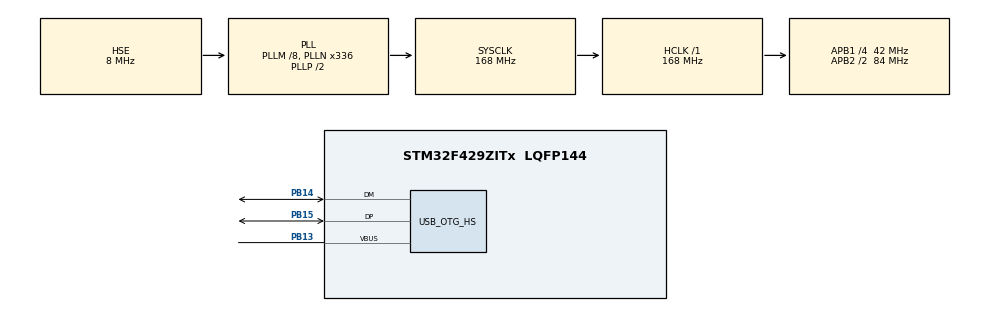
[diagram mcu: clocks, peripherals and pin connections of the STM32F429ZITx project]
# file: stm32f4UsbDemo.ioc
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Mcu.Family=STM32F4
Mcu.Name=STM32F429ZITx
Mcu.Package=LQFP144
NVIC.OTG_HS_IRQn=true\:0\:0\:false\:false\:true\:false
NVIC.PriorityGroup=NVIC_PRIORITYGROUP_4
PB13.Mode=Activate_VBUS_FS
PB13.Signal=USB_OTG_HS_VBUS
PB14.Mode=Device_Only_FS
PB14.Signal=USB_OTG_HS_DM
PB15.Mode=Device_Only_FS
PB15.Signal=USB_OTG_HS_DP
PH0/OSC_IN.Mode=HSE-External-Oscillator
PH0/OSC_IN.Signal=RCC_OSC_IN
PH1/OSC_OUT.Mode=HSE-External-Oscillator
PH1/OSC_OUT.Signal=RCC_OSC_OUT
ProjectManager.HeapSize=0x2000
ProjectManager.StackSize=0x4000
ProjectManager.TargetToolchain=MDK-ARM V5
RCC.48MHZClocksFreq_Value=48000000
RCC.AHBFreq_Value=168000000
RCC.APB1CLKDivider=RCC_HCLK_DIV4
RCC.APB1Freq_Value=42000000
RCC.APB1TimFreq_Value=84000000
RCC.APB2CLKDivider=RCC_HCLK_DIV2
RCC.APB2Freq_Value=84000000
RCC.APB2TimFreq_Value=168000000
RCC.CortexFreq_Value=168000000
RCC.HCLKFreq_Value=168000000
RCC.HSE_VALUE=8000000
RCC.HSI_VALUE=16000000
RCC.LSE_VALUE=32768
RCC.PLLM=8
RCC.PLLN=336
RCC.PLLQ=7
RCC.SYSCLKFreq_VALUE=168000000
RCC.SYSCLKSource=RCC_SYSCLKSOURCE_PLLCLK
RCC.VCOOutputFreq_Value=336000000
USB_DEVICE.CLASS_NAME_HS=CDC
USB_DEVICE.VirtualMode-CDC_HS=Cdc
USB_DEVICE.VirtualModeHS=Cdc_HS
USB_OTG_HS.VirtualMode-Device_Only_FS=Device_Only_FS
VP_USB_DEVICE_VS_USB_DEVICE_CDC_HS.Mode=CDC_HS
board=custom

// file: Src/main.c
/* USER CODE BEGIN Header */
/**
  ******************************************************************************
  * @file           : main.c
  * @brief          : Main program body
  ******************************************************************************
  ** This notice applies to any and all portions of this file
  * that are not between comment pairs USER CODE BEGIN and
  * USER CODE END. Other portions of this file, whether
  * inserted by the user or by software development tools
  * are owned by their respective copyright owners.
  *
  * COPYRIGHT(c) 2019 STMicroelectronics
  *
  * Redistribution and use in source and binary forms, with or without modification,
  * are permitted provided that the following conditions are met:
  *   1. Redistributions of source code must retain the above copyright notice,
  *      this list of conditions and the following disclaimer.
  *   2. Redistributions in binary form must reproduce the above copyright notice,
  *      this list of conditions and the following disclaimer in the documentation
  *      and/or other materials provided with the distribution.
  *   3. Neither the name of STMicroelectronics nor the names of its contributors
  *      may be used to endorse or promote products derived from this software
  *      without specific prior written permission.
  *
  * THIS SOFTWARE IS PROVIDED BY THE COPYRIGHT HOLDERS AND CONTRIBUTORS "AS IS"
  * AND ANY EXPRESS OR IMPLIED WARRANTIES, INCLUDING, BUT NOT LIMITED TO, THE
  * IMPLIED WARRANTIES OF MERCHANTABILITY AND FITNESS FOR A PARTICULAR PURPOSE ARE
  * DISCLAIMED. IN NO EVENT SHALL THE COPYRIGHT HOLDER OR CONTRIBUTORS BE LIABLE
  * FOR ANY DIRECT, INDIRECT, INCIDENTAL, SPECIAL, EXEMPLARY, OR CONSEQUENTIAL
  * DAMAGES (INCLUDING, BUT NOT LIMITED TO, PROCUREMENT OF SUBSTITUTE GOODS OR
  * SERVICES; LOSS OF USE, DATA, OR PROFITS; OR BUSINESS INTERRUPTION) HOWEVER
  * CAUSED AND ON ANY THEORY OF LIABILITY, WHETHER IN CONTRACT, STRICT LIABILITY,
  * OR TORT (INCLUDING NEGLIGENCE OR OTHERWISE) ARISING IN ANY WAY OUT OF THE USE
  * OF THIS SOFTWARE, EVEN IF ADVISED OF THE POSSIBILITY OF SUCH DAMAGE.
  *
  ******************************************************************************
  */
/* USER CODE END Header */

#include "main.h"
#include "usb_device.h"

/* USER CODE BEGIN Includes */
#include "usbd_cdc_if.h"
#include "usbd_conf.h"
#include <stdio.h>
/* USER CODE END Includes */

/* USER CODE BEGIN PD */
#ifdef _GNUC_
#define PUTCHAR_PROTOTYPE int __io_putchar(int ch)
	#else
#define PUTCHAR_PROTOTYPE	int fputc(int ch, FILE *f)
#endif
/* USER CODE END PD */

/* USER CODE BEGIN PV */
extern PCD_HandleTypeDef hpcd_USB_OTG_HS;
/* USER CODE END PV */

void SystemClock_Config(void);
static void MX_GPIO_Init(void);

int main(void)
{

  /* MCU Configuration--------------------------------------------------------*/

  /* Reset of all peripherals, Initializes the Flash interface and the Systick. */
  HAL_Init();

  /* Configure the system clock */
  SystemClock_Config();

  /* Initialize all configured peripherals */
  MX_GPIO_Init();
  MX_USB_DEVICE_Init();
  /* USER CODE BEGIN 2 */
	HAL_PCD_Start(&hpcd_USB_OTG_HS);
  /* USER CODE END 2 */

  /* Infinite loop */
  while (1)
  {

    /* USER CODE BEGIN 3 */
		HAL_Delay(1000);
		//uint8_t buff[14] = "Hello world!\r\n";
		//CDC_Transmit_HS((uint8_t*) &buff, 14);
		printf("Hello world!\r\n");
  }
  /* USER CODE END 3 */
}

void SystemClock_Config(void)
{
  RCC_OscInitTypeDef RCC_OscInitStruct = {0};
  RCC_ClkInitTypeDef RCC_ClkInitStruct = {0};

  /**Configure the main internal regulator output voltage
  */
  __HAL_RCC_PWR_CLK_ENABLE();
  __HAL_PWR_VOLTAGESCALING_CONFIG(PWR_REGULATOR_VOLTAGE_SCALE1);
  /**Initializes the CPU, AHB and APB busses clocks
  */
  RCC_OscInitStruct.OscillatorType = RCC_OSCILLATORTYPE_HSE;
  RCC_OscInitStruct.HSEState = RCC_HSE_ON;
  RCC_OscInitStruct.PLL.PLLState = RCC_PLL_ON;
  RCC_OscInitStruct.PLL.PLLSource = RCC_PLLSOURCE_HSE;
  RCC_OscInitStruct.PLL.PLLM = 8;
  RCC_OscInitStruct.PLL.PLLN = 336;
  RCC_OscInitStruct.PLL.PLLP = RCC_PLLP_DIV2;
  RCC_OscInitStruct.PLL.PLLQ = 7;
  if (HAL_RCC_OscConfig(&RCC_OscInitStruct) != HAL_OK)
  {
    Error_Handler();
  }
  /**Initializes the CPU, AHB and APB busses clocks
  */
  RCC_ClkInitStruct.ClockType = RCC_CLOCKTYPE_HCLK|RCC_CLOCKTYPE_SYSCLK
                              |RCC_CLOCKTYPE_PCLK1|RCC_CLOCKTYPE_PCLK2;
  RCC_ClkInitStruct.SYSCLKSource = RCC_SYSCLKSOURCE_PLLCLK;
  RCC_ClkInitStruct.AHBCLKDivider = RCC_SYSCLK_DIV1;
  RCC_ClkInitStruct.APB1CLKDivider = RCC_HCLK_DIV4;
  RCC_ClkInitStruct.APB2CLKDivider = RCC_HCLK_DIV2;

  if (HAL_RCC_ClockConfig(&RCC_ClkInitStruct, FLASH_LATENCY_5) != HAL_OK)
  {
    Error_Handler();
  }
}

static void MX_GPIO_Init(void)
{

  /* GPIO Ports Clock Enable */
  __HAL_RCC_GPIOH_CLK_ENABLE();
  __HAL_RCC_GPIOB_CLK_ENABLE();

}

/* USER CODE BEGIN 4 */
PUTCHAR_PROTOTYPE
{
	while(!(CDC_Transmit_HS((uint8_t*) &ch, 1) == USBD_OK))
	{
	}
	return ch;
}
/* USER CODE END 4 */

void Error_Handler(void)
{
}

/************************ (C) COPYRIGHT STMicroelectronics *****END OF FILE****/
